# CY8C4245PVI_482 register map
File version: 0.1
PSoC 4200
Registers are 32-bit, read-write, no defined reset value unless marked. A register's access mark holds for its fields unless they carry their own. Offsets are from the block's base; lines under a group give offsets from that group; [hi:lo] are bit positions; {n}, {i} and the like mark numbered series; 'fields as' and 'values as' point back to an identical list; <NAME> marks a mode.

## Memory map
0x40060000 UART size 0xFCD — Serial Communication Block
0x40080004 IDAC_Low size 0xFF01 — IDAC
0x40080004 IDAC_High size 0xFF01 — IDAC
0x400F0072 Display_SS_Reg size 0x1
0x40100000 Opamp size 0xF09
0x401A0000 ADC size 0xF05 — Sequencing SAR ADC

## Display_SS_Reg
Base 0x400F0072
0x00 Display_SS_Reg_CONTROL_REG 8-bit

## Opamp
Base 0x40100000
0x00 CONTROL — Opamp control
0x04 RES_CONTROL — Opamp resistor control
0x0C STATUS — Opamp status
0xF00 OFFSET_TRIM — Opamp offset trim
0xF04 SLOPE_OFFSET_TRIM — Opamp slope offset trim
0xF08 TRIM — Opamp trim

## IDAC_Low — IDAC
Base 0x40080004
Same registers: IDAC_High 0x40080004
0x00 CSD_IDAC_POLARITY
0x04 CSD_IDAC
0xFEFC CSD_TRIM1 — CSD IDAC TRIM1
0xFF00 CSD_TRIM2 — CSD IDAC TRIM2

## ADC — Sequencing SAR ADC
Base 0x401A0000
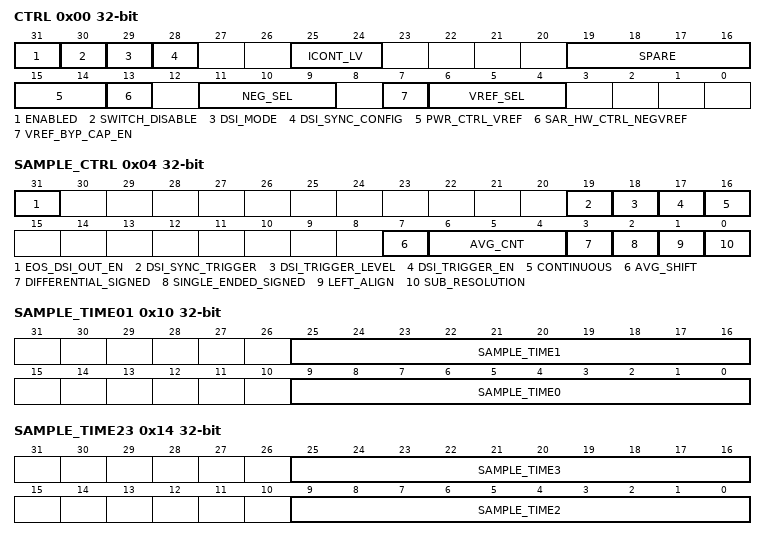
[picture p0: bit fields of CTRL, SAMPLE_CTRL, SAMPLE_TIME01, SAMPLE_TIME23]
0x00 CTRL — Analog control register
  [31] ENABLED — 0: SAR IP disabled, 1: SAR IP enabled.
  [30] SWITCH_DISABLE — Disable SAR sequencer from enabling routing switches
  [29] DSI_MODE — SAR sequencer takes configuration from DSI signals
  [28] DSI_SYNC_CONFIG — Synchronize the DSI config signals to peripheral clock domain
  [25:24] ICONT_LV — SARADC low power mode
  [19:16] SPARE — Spare controls
  [15:14] PWR_CTRL_VREF — VREF buffer low power mode.
  [13] SAR_HW_CTRL_NEGVREF — Hardware control: 0=firmware, 1=hardware.
  [11:9] NEG_SEL — SARADC internal NEG selection for Single ended conversion
  [7] VREF_BYP_CAP_EN — VREF bypass cap enable for when VREF buffer is on
  [6:4] VREF_SEL — SARADC internal VREF selection
0x04 SAMPLE_CTRL — Sample control register
  [31] EOS_DSI_OUT_EN — Enable to output EOS_INTR to DSI
  [19] DSI_SYNC_TRIGGER — 0: bypass clock domain synchronisation of the DSI trigger signal, 1: synchronize the DSI trigger signal to the SAR clock domain.
  [18] DSI_TRIGGER_LEVEL — 0: DSI trigger signal is a pulse input, 1: DSI trigger signal is a level inpu.t
  [17] DSI_TRIGGER_EN — 0: firmware trigger only, 1: enable hardware (DSI) trigger.
  [16] CONTINUOUS — 0: Wait for next FW_TRIGGER or hardware trigger before scanning enabled channels. 1: Continuously scan enabled channels..
  [7] AVG_SHIFT — Averaging shifting: after averaging the result is shifted right to fit in the sample resolution, i.e. 12 bits.
  [6:4] AVG_CNT — Averaging Count for channels that have over sampling enabled
  [3] DIFFERENTIAL_SIGNED — Output data from a differential conversion as a signed value
  [2] SINGLE_ENDED_SIGNED — Output data from a single ended conversion as a signed value
  [1] LEFT_ALIGN — Left align data in data[15:0], default data is right aligned in data[11:0], with sign extension to 16 bits if the channel is differential.
  [0] SUB_RESOLUTION — Conversion resolution for channels that have sub-resolution enabled (RESOLUTION=1) (otherwise resolution is 12-bit).
0x10 SAMPLE_TIME01 — Sample time specification ST0 and ST1
  [25:16] SAMPLE_TIME1
  [9:0] SAMPLE_TIME0 — Sample time0 (aperture) in ADC clock cycles
0x14 SAMPLE_TIME23 — Sample time specification ST2 and ST3
  [25:16] SAMPLE_TIME3, [9:0] SAMPLE_TIME2
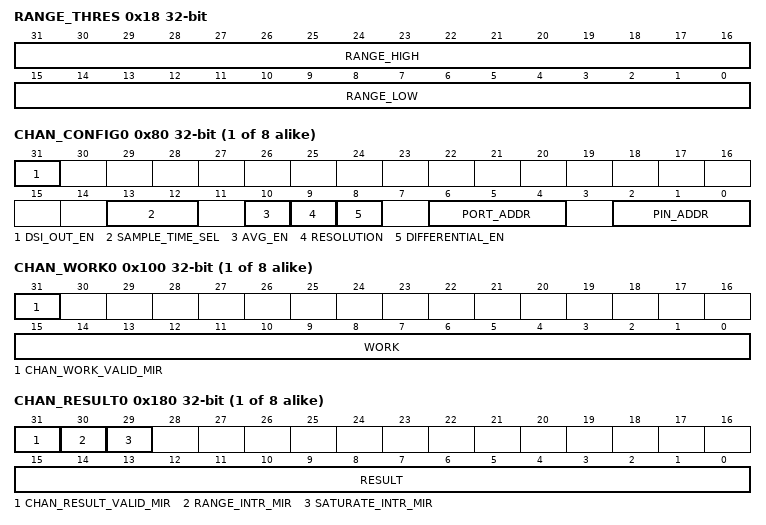
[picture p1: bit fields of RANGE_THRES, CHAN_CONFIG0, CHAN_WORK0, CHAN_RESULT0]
0x18 RANGE_THRES — Global range detect threshold register
  [31:16] RANGE_HIGH — High threshold for range detect
  [15:0] RANGE_LOW — Low threshold for range detect
0x1C RANGE_COND — Global range detect mode register
  [31:30] RANGE_COND — Range condition select
0x20 CHAN_EN — Enable bits for the channels
  [15:0] CHAN_EN — Channel enable. 0: the corresponding channel is disabled. 1: the corresponding channel is enabled, it will be included in the next scan.
0x24 START_CTRL — Start control register (firmware trigger)
  [0] FW_TRIGGER — When firmware writes a 1 here it will trigger the next scan of enabled channels
0x30 DFT_CTRL — DFT control register
{0x80+4i} CHAN_CONFIG{i} (i=0..7) — Channel{i} configuration register
  [31] DSI_OUT_EN — DSI data output enable for this channel
  [13:12] SAMPLE_TIME_SEL — Sample time select: select which of the 4 global sample times to use for this channel.
  [10] AVG_EN — Averaging enable for this channel. If set the AVG_CNT and AVG_SHIFT settings are used for sampling the addressed pin(s).
  [9] RESOLUTION — Resolution for this channel
  [8] DIFFERENTIAL_EN — Differential enable for this channel
  [6:4] PORT_ADDR — Address of the port that contains the pin to be sampled by this channel
  [2:0] PIN_ADDR — Address of the pin to be sampled by this channel
{0x100+4i} CHAN_WORK{i} (i=0..7) — Channel{i} working data register
  [31] CHAN_WORK_VALID_MIR ro — Mirror bit of corresponding bit in SAR_CHAN_WORK_VALID register
  [15:0] WORK ro — SAR conversion working data of the channel
{0x180+4i} CHAN_RESULT{i} (i=0..7) — Channel{i} result data register
  [31] CHAN_RESULT_VALID_MIR ro — Mirror bit of corresponding bit in SAR_SATURATE_INTR register
  [30] RANGE_INTR_MIR ro — Mirror bit of corresponding bit in SAR_RANGE_INTR register
  [29] SATURATE_INTR_MIR ro — Mirror bit of corresponding bit in SAR_SATURATE_INTR register
  [15:0] RESULT ro — SAR conversion result of the channel. The data is copied here from the WORK field after all enabled channels in this scan have been sampled.
0x200 CHAN_WORK_VALID — Channel working data register valid bits
  [15:0] CHAN_WORK_VALID ro — If set the corresponding WORK data is valid, i.e. was already sampled during the current scan.
0x204 CHAN_RESULT_VALID — Channel result data register valid bits
  [15:0] CHAN_RESULT_VALID ro — If set the corresponding RESULT data is valid, i.e. was sampled during the last scan.
0x208 STATUS — Current status of internal SAR registers (mostly for debug)
0x20C AVG_STAT — Current averaging status (for debug)
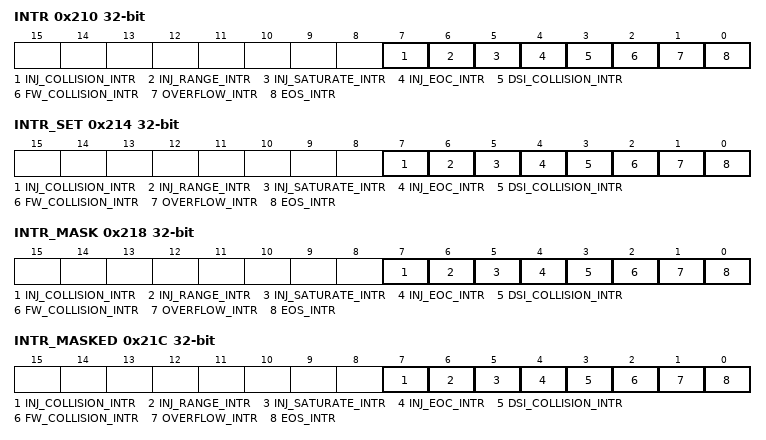
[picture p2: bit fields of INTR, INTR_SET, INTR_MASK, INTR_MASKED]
0x210 INTR — Interrupt request register
  [7] INJ_COLLISION_INTR — Injection Collision Interrupt
  [6] INJ_RANGE_INTR — Injection Range detect Interrupt
  [5] INJ_SATURATE_INTR — Injection Saturation Interrupt
  [4] INJ_EOC_INTR — Injection End of Conversion Interrupt
  [3] DSI_COLLISION_INTR — DSI Collision Interrupt
  [2] FW_COLLISION_INTR — Firmware Collision Interrupt
  [1] OVERFLOW_INTR — Overflow Interrupt
  [0] EOS_INTR — End Of Scan Interrupt
0x214 INTR_SET — Not really a register, intended for verification/debug. When read, this register reflects the interrupt request register.
  fields as INTR
0x218 INTR_MASK — Interrupt mask register
  fields as INTR
0x21C INTR_MASKED — Interrupt masked request register
  fields as INTR
0x220 SATURATE_INTR — Saturate interrupt request register
  [15:0] SATURATE_INTR — Saturate Interrupt
0x224 SATURATE_INTR_SET — Saturate interrupt set request register
  [15:0] SATURATE_INTR — Saturate Interrupt
0x228 SATURATE_INTR_MASK — Saturate interrupt mask register
  [15:0] SATURATE_INTR — Saturate Interrupt
0x22C SATURATE_INTR_MASKED — Saturate interrupt masked request register
  [15:0] SATURATE_INTR — Saturate Interrupt
0x230 RANGE_INTR — Range detect interrupt request register
  [15:0] RANGE_INTR — Range detect Interrupt
0x234 RANGE_INTR_SET — Range detect interrupt set request register
  [15:0] RANGE_INTR — Range detect Interrupt
0x238 RANGE_INTR_MASK — Range detect interrupt mask register
  [15:0] RANGE_INTR — Range detect Interrupt
0x23C RANGE_INTR_MASKED — Range interrupt masked request register
  [15:0] RANGE_INTR — Range detect Interrupt
0x240 INTR_CAUSE — Interrupt cause register
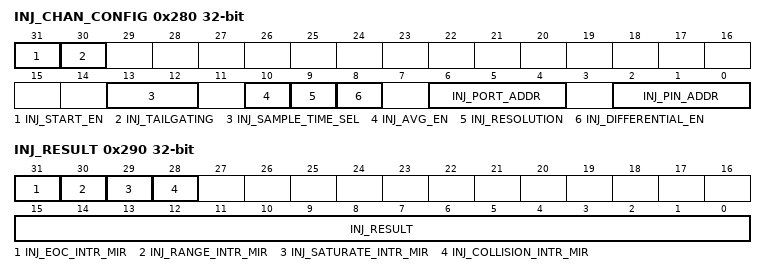
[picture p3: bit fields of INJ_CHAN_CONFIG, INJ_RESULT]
0x280 INJ_CHAN_CONFIG — Injection channel configuration register
  [31] INJ_START_EN — Set by firmware to enable the injection channel
  [30] INJ_TAILGATING — Injection channel tailgating
  [13:12] INJ_SAMPLE_TIME_SEL — Sample time select: select which of the 4 global sample times to use for this channel.
  [10] INJ_AVG_EN — Averaging enable for this channel. If set the AVG_CNT and AVG_SHIFT settings are used for sampling the addressed pin(s).
  [9] INJ_RESOLUTION — Resolution for this channel
  [8] INJ_DIFFERENTIAL_EN — Differential enable for this channel
  [6:4] INJ_PORT_ADDR — Address of the port that contains the pin to be sampled by this channel
  [2:0] INJ_PIN_ADDR — Address of the pin to be sampled by this channel
0x290 INJ_RESULT — Injection channel result register
  [31] INJ_EOC_INTR_MIR ro — Mirror bit of corresponding bit in SAR_INTR register
  [30] INJ_RANGE_INTR_MIR ro — Mirror bit of corresponding bit in SAR_INTR register
  [29] INJ_SATURATE_INTR_MIR ro — Mirror bit of corresponding bit in SAR_INTR register
  [28] INJ_COLLISION_INTR_MIR ro — Mirror bit of corresponding bit in SAR_INTR register
  [15:0] INJ_RESULT ro — SAR conversion result of the channel
0x300 MUX_SWITCH0 — SARMUX Firmware switch controls
0x304 MUX_SWITCH_CLEAR0 — SARMUX Firmware switch control clear
0x308 MUX_SWITCH1 — SARMUX Firmware switch controls
0x30C MUX_SWITCH_CLEAR1 — SARMUX Firmware switch control clear
0x340 MUX_SWITCH_HW_CTRL — SARMUX switch hardware control
0x348 MUX_SWITCH_STATUS — SARMUX switch status
0x380 PUMP_CTRL — Switch pump control
0xF00 ANA_TRIM — Analog trim register
0xF04 WOUNDING — SAR wounding register
  [1:0] WOUND_RESOLUTION ro — Maximum SAR resolution allowed
